# V32F20x_CM33 register map
File version: 1.0.3
CPU: CM33 r0p4, little endian, MPU, FPU, DSP, 3 interrupt priority bits, 8 SAU regions
Registers are 32-bit, read-write, reset 0x0 unless marked. A register's access mark holds for its fields unless they carry their own. Offsets are from the block's base; [hi:lo] are bit positions; {n}, {i} and the like mark numbered series.

## RTCANA — RTCANA Peripheral Interface
Base 0x40103800
Same registers: SEC_RTCANA 0x50103800
0x04 SWRSTPSWD wo — RTC soft reset password register
  [0] PASSWORD
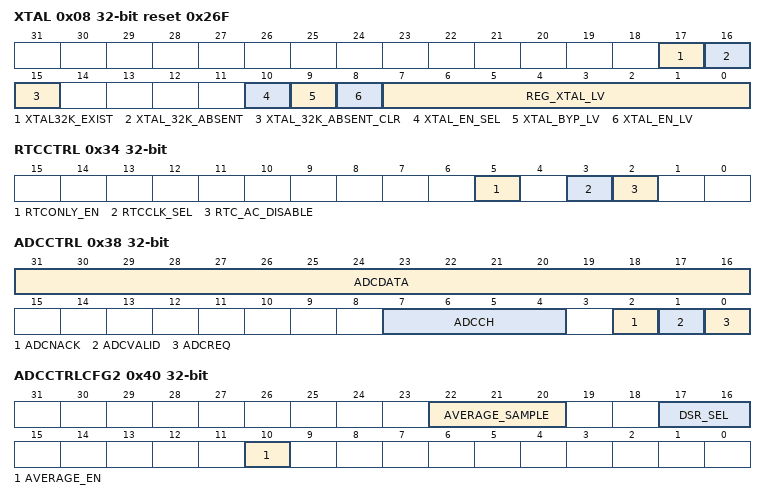
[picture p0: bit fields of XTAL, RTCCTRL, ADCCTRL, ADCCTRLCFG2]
0x08 XTAL reset 0x26F — External 32768Hz OSC control register
  [17] XTAL32K_EXIST — XTAL 32K current status:
  [16] XTAL_32K_ABSENT — When high, indicate xtal 32k is absent once.
  [15] XTAL_32K_ABSENT_CLR — Write 0 to clear XTAL_32K_ABSENT bit.
  [10] XTAL_EN_SEL — Enable of XTAL (XOL) selection
  [9] XTAL_BYP_LV — External active crystal input selectable signal high active
  [8] XTAL_EN_LV — Enable of XTAL LV:
  [7:0] REG_XTAL_LV — Register to control operating AGC function and oscillate state check function of crystal OSC
0x1C ANALOCK — Analog lock register
  [0] ANA_LOCK — Analog lock write 0xBEEF_BEEF to lock analog control register write 0xFEEBFEEB to unlock
0x34 RTCCTRL — RTC Analog control register
  [5] RTCONLY_EN — RTC Only enable
  [3] RTCCLK_SEL — RTC Clock select
  [2] RTC_AC_DISABLE — RTC Auto calibration disable
0x38 ADCCTRL — ADC control register
  [31:16] ADCDATA — ADC conversion result for the analog request
  [7:4] ADCCH — ADC channel select
  [2] ADCNACK — ADC conversion nack flag
  [1] ADCVALID — 1: ADC conversion is finished.
  [0] ADCREQ — ADC analog request.
0x3C ADCCTRLCFG — ADC configuration register
  [31:24] ADC_CLK_DIV — The divide of ADC clock source clock is 6.5Mhz
0x40 ADCCTRLCFG2 — ADC configuration register 2
  [22:20] AVERAGE_SAMPLE — The average sample configuration.
  [17:16] DSR_SEL — CIC down sample rate configure
  [10] AVERAGE_EN — The average enable configuration for temperature channel
0x58 RTCCTRLPSWD — RTCCTRL access protection register
  [0] UNLOCK — This bit indicates the RTCANA_RTCCTRL has been unlocked and is ready for configuration
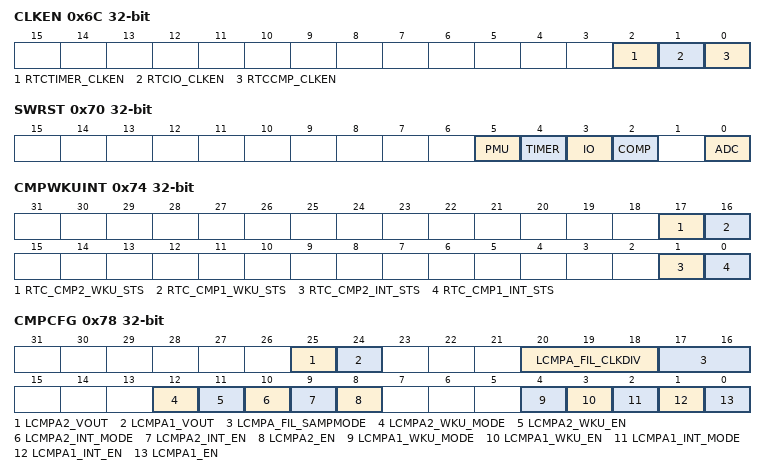
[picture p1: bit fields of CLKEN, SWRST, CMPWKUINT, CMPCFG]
0x6C CLKEN — Analog submodule clock enable register
  [2] RTCTIMER_CLKEN — RTC timer clock enable
  [1] RTCIO_CLKEN — RTC IO clock enable
  [0] RTCCMP_CLKEN — RTC CMP clock enable
0x70 SWRST — RTC submodule soft reset register
  [5] PMU — RTC PMU soft reset request
  [4] TIMER — RTC timer soft reset request
  [3] IO — RTC IO soft reset request
  [2] COMP — RTC comparator soft reset request
  [0] ADC — RTC ADC soft reset request
0x74 CMPWKUINT — RTC CMP wakeup interrupt status register
  [17] RTC_CMP2_WKU_STS — RTC CMP2 wakeup status
  [16] RTC_CMP1_WKU_STS — RTC CMP1 wakeup status
  [1] RTC_CMP2_INT_STS — RTC CMP2 interrupt status
  [0] RTC_CMP1_INT_STS — RTC CMP1 interrupt status
0x78 CMPCFG — RTC CMP configuration register
  [25] LCMPA2_VOUT — CMP2 in rtc_wrap vout status
  [24] LCMPA1_VOUT — CMP1 in rtc_wrap vout status
  [20:18] LCMPA_FIL_CLKDIV — CMP clock divider
  [17:16] LCMPA_FIL_SAMPMODE — CMP sample mode
  [12] LCMPA2_WKU_MODE — CMP2 wakeup mode configure
  [11] LCMPA2_WKU_EN — CMP2 wakeup enable configure
  [10] LCMPA2_INT_MODE — CMP2 interrupt mode
  [9] LCMPA2_INT_EN — CMP2 interrupt enable
  [8] LCMPA2_EN — CMP2 enable register
  [4] LCMPA1_WKU_MODE — CMP1 wakeup mode configure
  [3] LCMPA1_WKU_EN — CMP1 wakeup enable configure
  [2] LCMPA1_INT_MODE — CMP1 interrupt mode
  [1] LCMPA1_INT_EN — CMP1 interrupt enable
  [0] LCMPA1_EN — CMP1 enable register
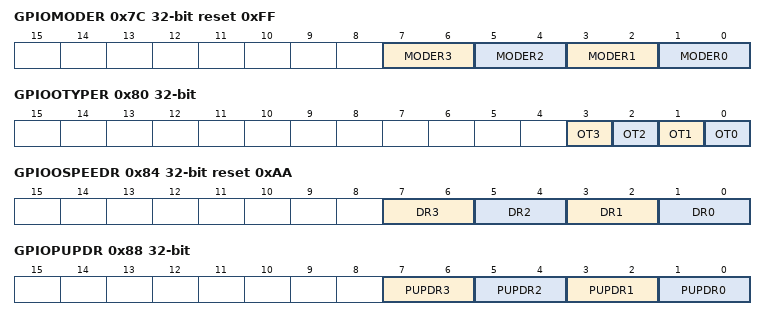
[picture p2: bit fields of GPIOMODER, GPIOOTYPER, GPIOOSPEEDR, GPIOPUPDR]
0x7C GPIOMODER reset 0xFF — RTC GPIO port mode register
  [7:6] MODER3 — These bits are written by software to configure the PI8 direction mode
  [5:4] MODER2 — These bits are written by software to configure the PC15 direction mode
  [3:2] MODER1 — These bits are written by software to configure the PC14 direction mode
  [1:0] MODER0 — These bits are written by software to configure the PC13 direction mode
0x80 GPIOOTYPER — RTC GPIO port output type register
  [3] OT3 — These bits are written by software to configure the output type of the PI8 port
  [2] OT2 — These bits are written by software to configure the output type of the PC15 port
  [1] OT1 — These bits are written by software to configure the output type of the PC14 port
  [0] OT0 — These bits are written by software to configure the output type of the PC13 port
0x84 GPIOOSPEEDR reset 0xAA — RTC GPIO output drive strength
  [7:6] DR3 — PI8 output drive strength
  [5:4] DR2 — PC15 output drive strength
  [3:2] DR1 — PC14 output drive strength
  [1:0] DR0 — PC13 output drive strength
0x88 GPIOPUPDR — RTC GPIO port pull-up and pull-down register
  [7:6] PUPDR3 — These bits are written by software to configure the PI8 pull up or pull down
  [5:4] PUPDR2 — These bits are written by software to configure the PC15 pull up or pull down
  [3:2] PUPDR1 — These bits are written by software to configure the PC14 pull up or pull down
  [1:0] PUPDR0 — These bits are written by software to configure the PC13 pull up or pull down
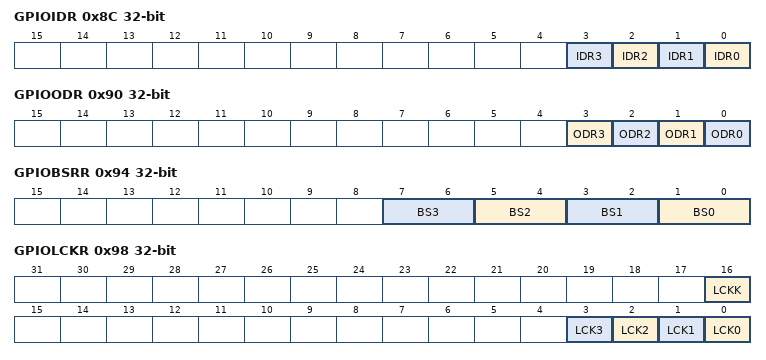
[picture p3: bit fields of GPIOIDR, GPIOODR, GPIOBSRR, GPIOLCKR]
0x8C GPIOIDR ro — RTC GPIO port input data register
  [n] IDR{n} (n=0..3) — This bit is read only and can be accessed in word mode only
0x90 GPIOODR — RTC GPIO port output data register
  [3] ODR3 — This bit can be read and written by software for PI8
  [2] ODR2 — These bits can be read and written by software for PC15
  [1] ODR1 — These bits can be read and written by software for PC14
  [0] ODR0 — These bits can be read and written by software for PC13
0x94 GPIOBSRR wo — RTC GPIO port bit set/reset register
  [2n+1:2n] BS{n} (n=0..3) — These bits are write only
0x98 GPIOLCKR — RTC GPIO port lock control register
  [16] LCKK — This bit can be read in any time
  [3] LCK3 — PI8 configure lock signal
  [2] LCK2 — PC15 configure lock signal
  [1] LCK1 — PC14 configure lock signal
  [0] LCK0 — PC13 configure lock signal
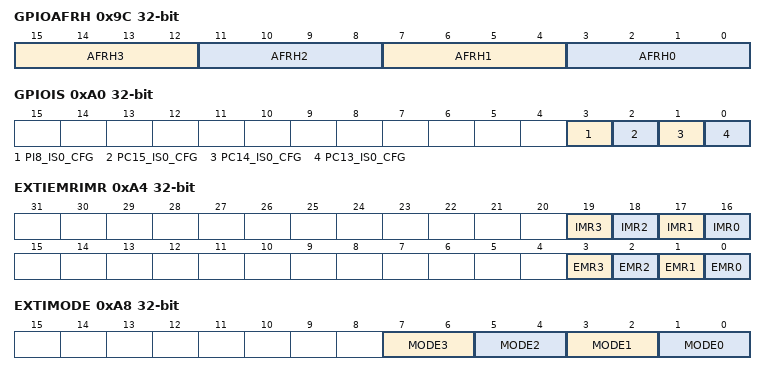
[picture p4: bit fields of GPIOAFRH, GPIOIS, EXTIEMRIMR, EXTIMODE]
0x9C GPIOAFRH — RTC GPIO port alternate function selection register
  [15:12] AFRH3 — PI8 Alternate function selection refer to GPIO alternate function table for details
  [11:8] AFRH2 — PC15 Alternate function selection refer to GPIO alternate function table for details
  [7:4] AFRH1 — PC14 Alternate function selection refer to GPIO alternate function table for details
  [3:0] AFRH0 — PC13 Alternate function selection refer to GPIO alternate function table for details
0xA0 GPIOIS — RTC GPIO IS configure register
  [3] PI8_IS0_CFG — PI8 IS configure
  [2] PC15_IS0_CFG — PC15 IS configure
  [1] PC14_IS0_CFG — PC14 IS configure
  [0] PC13_IS0_CFG — PC13 IS configure
0xA4 EXTIEMRIMR — RTC IO EXTI wakeup and interrupt mask register
  [19] IMR3 — Interrupt mask on PI8 EXTI
  [18] IMR2 — Interrupt mask on PC15 EXTI
  [17] IMR1 — Interrupt mask on PC14 EXTI
  [16] IMR0 — Interrupt mask on PC13 EXTI
  [3] EMR3 — Wakeup mask on PI8 EXTI
  [2] EMR2 — Wakeup mask on PC15 EXTI
  [1] EMR1 — Wakeup mask on PC14 EXTI
  [0] EMR0 — Wakeup mask on PC13 EXTI
0xA8 EXTIMODE — RTC IO EXTI interrupt and wakeup mode configure register
  [7:6] MODE3 — The mode of PI8 interrupt and wakeup configure
  [5:4] MODE2 — The mode of PC15 interrupt and wakeup configure
  [3:2] MODE1 — The mode of PC14 interrupt and wakeup configure:
  [1:0] MODE0 — The mode of PC13 interrupt and wakeup configure
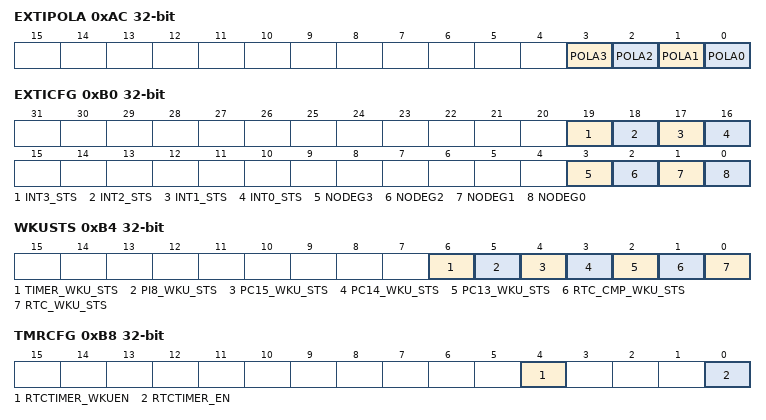
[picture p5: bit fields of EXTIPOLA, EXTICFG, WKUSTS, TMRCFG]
0xAC EXTIPOLA — RTC IO EXTI interrupt and wakeup polarity configure register
  [3] POLA3 — The polarity of PI8 interrupt and wakeup configure
  [2] POLA2 — The polarity of PC15 interrupt and wakeup configure
  [1] POLA1 — The polarity of PC14 interrupt and wakeup configure
  [0] POLA0 — The polarity of PC13 interrupt and wakeup configure
0xB0 EXTICFG — RTC IO external input signal deglitch and int clear control register
  [19] INT3_STS — PI8 Interrupt status signal write 1 to clear and auto clear itself
  [18] INT2_STS — PC15 Interrupt status signal write 1 to clear and auto clear itself
  [17] INT1_STS — PC14 Interrupt status signal write 1 to clear and auto clear itself
  [16] INT0_STS — PC13 Interrupt status signal write 1 to clear and auto clear itself
  [3] NODEG3 — PI8 external input signal deglitch disable
  [2] NODEG2 — PC15 external input signal deglitch disable
  [1] NODEG1 — PC14 external input signal deglitch disable
  [0] NODEG0 — PC13 external input signal deglitch disable
0xB4 WKUSTS — RTC only wakeup status register
  [6] TIMER_WKU_STS — Waked up by Timer:
  [5] PI8_WKU_STS — Waked up by PI8 signal:
  [4] PC15_WKU_STS — Waked up by PC15 signal:
  [3] PC14_WKU_STS — Waked up by PC14 signal:
  [2] PC13_WKU_STS — Waked up by PC13 signal:
  [1] RTC_CMP_WKU_STS — Waked up by CMP in RTC:
  [0] RTC_WKU_STS — Waked up by RTC:
0xB8 TMRCFG — RTC timer configuration register
  [4] RTCTIMER_WKUEN — RTC timer wakeup enable
  [0] RTCTIMER_EN — RTC timer enable
0xBC TMRCNT — RTC timer count register
  [31:0] TMR_CNT — Timer count value
